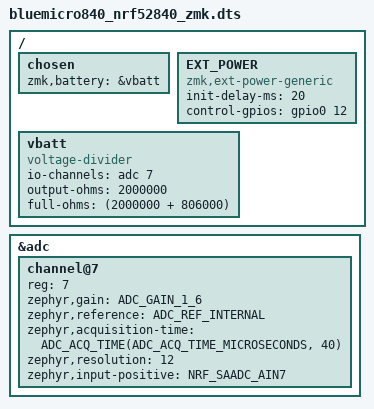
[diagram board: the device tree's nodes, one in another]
/*
 * Copyright (c) 2026 Pete Johanson, Derek Schmell
 *
 * SPDX-License-Identifier: MIT
 */

#include <../boards/jpconstantineau/bluemicro840/bluemicro840.dts>
#include <common/nordic/nrf52840_uf2_boot_mode.dtsi>

/ {
    chosen {
        zmk,battery = &vbatt;
    };

    // Node name must match original "EXT_POWER" label to preserve user settings.
    EXT_POWER {
        compatible = "zmk,ext-power-generic";
        init-delay-ms = <20>;
        control-gpios = <&gpio0 12 GPIO_ACTIVE_HIGH>;
    };

    vbatt: vbatt {
        compatible = "voltage-divider";
        io-channels = <&adc 7>;
        output-ohms = <2000000>;
        full-ohms = <(2000000 + 806000)>;
    };

};

&adc {
    #address-cells = <1>;
    #size-cells = <0>;
    status = "okay";

    channel@7 {
        reg = <7>;
        zephyr,gain = "ADC_GAIN_1_6";
        zephyr,reference = "ADC_REF_INTERNAL";
        zephyr,acquisition-time = <ADC_ACQ_TIME(ADC_ACQ_TIME_MICROSECONDS, 40)>;
        zephyr,resolution = <12>;
        zephyr,input-positive = <NRF_SAADC_AIN7>;
    };
};
